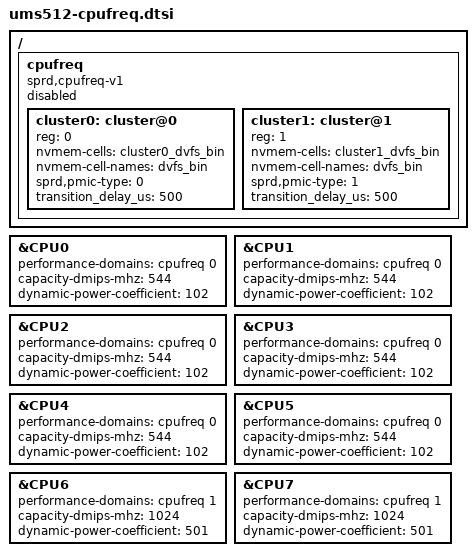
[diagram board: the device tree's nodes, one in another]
// SPDX-License-Identifier: (GPL-2.0+ OR MIT)
/*
 * Unisoc UMS512 SoC CPUFREQ DVFS DTS file
 *
 * Copyright (C) 2026 Veynamer <veyr1thalone@gmail.com>
 */

/ {
	cpufreq: cpufreq {
		compatible = "sprd,cpufreq-v1";
		#performance-domain-cells = <1>;
		#address-cells = <1>;
		#size-cells = <0>;

		status = "disabled";

		cluster0: cluster@0 {
			reg = <0>;
			nvmem-cells = <&cluster0_dvfs_bin>;
			nvmem-cell-names = "dvfs_bin";
			sprd,pmic-type = <0>;
			transition_delay_us = <500>;
		};

		cluster1: cluster@1 {
			reg = <1>;
			nvmem-cells = <&cluster1_dvfs_bin>;
			nvmem-cell-names = "dvfs_bin";
			sprd,pmic-type = <1>;
			transition_delay_us = <500>;
		};
	};
};

&CPU0 {
	performance-domains = <&cpufreq 0>;
	capacity-dmips-mhz = <544>;
	dynamic-power-coefficient = <102>;
};

&CPU1 {
	performance-domains = <&cpufreq 0>;
	capacity-dmips-mhz = <544>;
	dynamic-power-coefficient = <102>;
};

&CPU2 {
	performance-domains = <&cpufreq 0>;
	capacity-dmips-mhz = <544>;
	dynamic-power-coefficient = <102>;
};

&CPU3 {
	performance-domains = <&cpufreq 0>;
	capacity-dmips-mhz = <544>;
	dynamic-power-coefficient = <102>;
};

&CPU4 {
	performance-domains = <&cpufreq 0>;
	capacity-dmips-mhz = <544>;
	dynamic-power-coefficient = <102>;
};

&CPU5 {
	performance-domains = <&cpufreq 0>;
	capacity-dmips-mhz = <544>;
	dynamic-power-coefficient = <102>;
};

&CPU6 {
	performance-domains = <&cpufreq 1>;
	capacity-dmips-mhz = <1024>;
	dynamic-power-coefficient = <501>;
};

&CPU7 {
	performance-domains = <&cpufreq 1>;
	capacity-dmips-mhz = <1024>;
	dynamic-power-coefficient = <501>;
};
